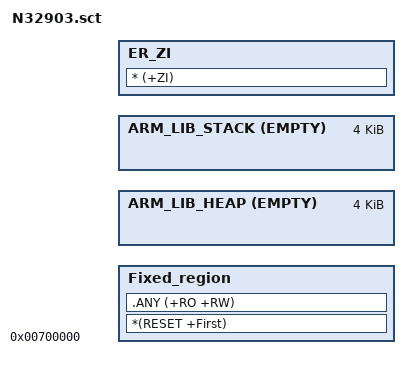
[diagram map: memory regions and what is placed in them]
;*------------------------------------------------------------------------------
;*      Linker scatter for running in external SDRAM on the n3290x
;*----------------------------------------------------------------------------*/

Load_region 0x700000
{
    Fixed_region 0x700000
    {   
       *(RESET +First)
       .ANY (+RO +RW)
    }

    ARM_LIB_HEAP +0 EMPTY 0x1000
    {
    }

    ARM_LIB_STACK +0 EMPTY 0x1000
    {
    }

    ; Application ZI data (.bss)
    ER_ZI +0
    {
        * (+ZI)
    }
}

